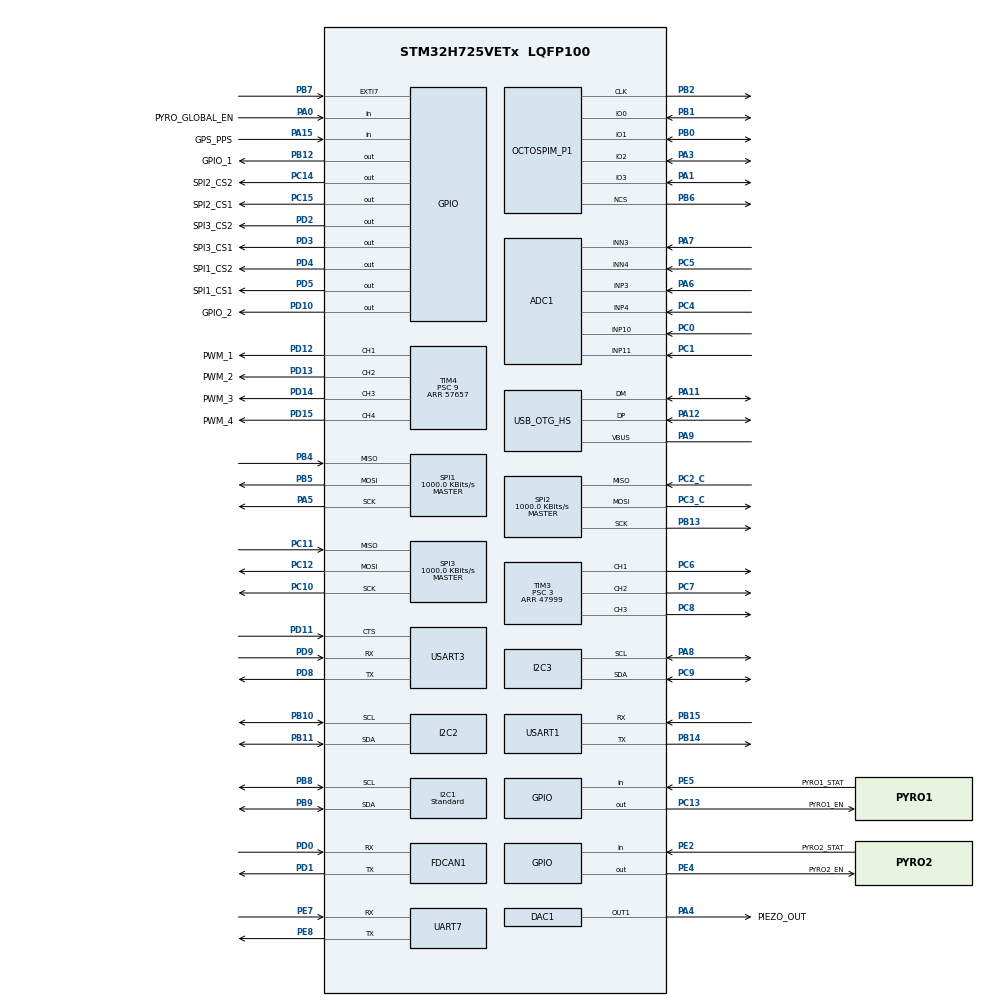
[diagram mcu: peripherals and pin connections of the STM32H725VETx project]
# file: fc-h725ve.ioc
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ADC1.Channel-0\#ChannelRegularConversion=ADC_CHANNEL_3
ADC1.NbrOfConversionFlag=1
ADC1.OffsetNumber-0\#ChannelRegularConversion=ADC_OFFSET_NONE
ADC1.OffsetSignedSaturation-0\#ChannelRegularConversion=DISABLE
ADC1.Rank-0\#ChannelRegularConversion=1
ADC1.SamplingTime-0\#ChannelRegularConversion=ADC_SAMPLETIME_1CYCLE_5
ADC1.SingleDiff-0\#ChannelRegularConversion=ADC_DIFFERENTIAL_ENDED
ADC1.master=1
CORTEX_M7.CPU_ICache=Enabled
CORTEX_M7.default_mode_Activation=1
DAC1.DAC_Channel-DAC_OUT1=DAC_CHANNEL_1
DAC1.DAC_Trigger-DAC_OUT1=DAC_TRIGGER_T5_TRGO
Dma.DAC1_CH1.0.Direction=DMA_MEMORY_TO_PERIPH
Dma.DAC1_CH1.0.EventEnable=DISABLE
Dma.DAC1_CH1.0.FIFOMode=DMA_FIFOMODE_DISABLE
Dma.DAC1_CH1.0.Instance=DMA1_Stream0
Dma.DAC1_CH1.0.MemDataAlignment=DMA_MDATAALIGN_BYTE
Dma.DAC1_CH1.0.MemInc=DMA_MINC_ENABLE
Dma.DAC1_CH1.0.Mode=DMA_CIRCULAR
Dma.DAC1_CH1.0.PeriphDataAlignment=DMA_PDATAALIGN_BYTE
Dma.DAC1_CH1.0.PeriphInc=DMA_PINC_DISABLE
Dma.DAC1_CH1.0.Polarity=HAL_DMAMUX_REQ_GEN_RISING
Dma.DAC1_CH1.0.Priority=DMA_PRIORITY_LOW
Dma.DAC1_CH1.0.RequestNumber=1
Dma.DAC1_CH1.0.SignalID=NONE
Dma.DAC1_CH1.0.SyncEnable=DISABLE
Dma.DAC1_CH1.0.SyncPolarity=HAL_DMAMUX_SYNC_NO_EVENT
Dma.DAC1_CH1.0.SyncRequestNumber=1
Dma.DAC1_CH1.0.SyncSignalID=NONE
Dma.Request0=DAC1_CH1
FDCAN1.CalculateBaudRateNominal=1000000
FDCAN1.CalculateTimeBitNominal=1000
FDCAN1.CalculateTimeQuantumNominal=333.3333333333333
FDCAN1.ClockCalibrationCCU=DISABLE
FDCAN1.DataPrescaler=8
FDCAN1.FrameFormat=FDCAN_FRAME_FD_NO_BRS
FDCAN1.NominalPrescaler=32
I2C1.I2C_Speed_Mode=I2C_Standard
I2C1.Timing=0x10B0DCFB
I2C2.Timing=0x10B0DCFB
I2C3.Timing=0x10B0DCFB
Mcu.Family=STM32H7
Mcu.Name=STM32H725VETx
Mcu.Package=LQFP100
NVIC.DMA1_Stream0_IRQn=true\:5\:0\:true\:false\:true\:false\:true\:true
NVIC.EXTI9_5_IRQn=true\:5\:0\:true\:false\:true\:true\:true\:true
NVIC.OTG_HS_IRQn=true\:5\:0\:true\:false\:true\:false\:true\:true
NVIC.PriorityGroup=NVIC_PRIORITYGROUP_4
NVIC.TIM6_DAC_IRQn=true\:15\:0\:false\:false\:true\:false\:true\:true
NVIC.TimeBase=TIM6_DAC_IRQn
NVIC.TimeBaseIP=TIM6
PA0.GPIO_Label=PYRO_GLOBAL_EN
PA0.Signal=GPIO_Input
PA1.Mode=OCTOSPI1_IOL_Port1L
PA1.Signal=OCTOSPIM_P1_IO3
PA11.Mode=Device_Only_FS
PA11.Signal=USB_OTG_HS_DM
PA12.Mode=Device_Only_FS
PA12.Signal=USB_OTG_HS_DP
PA13(JTMS/SWDIO).Mode=Trace_Asynchronous_SW
PA13(JTMS/SWDIO).Signal=DEBUG_JTMS-SWDIO
PA14(JTCK/SWCLK).Mode=Trace_Asynchronous_SW
PA14(JTCK/SWCLK).Signal=DEBUG_JTCK-SWCLK
PA15(JTDI).GPIO_Label=GPS_PPS
PA15(JTDI).Signal=GPIO_Input
PA3.Mode=OCTOSPI1_IOL_Port1L
PA3.Signal=OCTOSPIM_P1_IO2
PA4.GPIO_Label=PIEZO_OUT
PA4.Signal=COMP_DAC11_group
PA5.Mode=Full_Duplex_Master
PA5.Signal=SPI1_SCK
PA6.Signal=ADCx_INP3
PA7.Signal=ADCx_INN3
PA8.GPIO_Pu=GPIO_NOPULL
PA8.Mode=I2C
PA8.Signal=I2C3_SCL
PA9.Mode=Activate_VBUS_FS
PA9.Signal=USB_OTG_HS_VBUS
PB0.Mode=OCTOSPI1_IOL_Port1L
PB0.Signal=OCTOSPIM_P1_IO1
PB1.Mode=OCTOSPI1_IOL_Port1L
PB1.Signal=OCTOSPIM_P1_IO0
PB10.GPIO_Pu=GPIO_NOPULL
PB10.Mode=I2C
PB10.Signal=I2C2_SCL
PB11.GPIO_Pu=GPIO_NOPULL
PB11.Mode=I2C
PB11.Signal=I2C2_SDA
PB12.GPIO_Label=GPIO_1
PB12.Signal=GPIO_Output
PB13.Mode=Full_Duplex_Master
PB13.Signal=SPI2_SCK
PB14.Mode=Asynchronous
PB14.Signal=USART1_TX
PB15.Mode=Asynchronous
PB15.Signal=USART1_RX
PB2.Mode=O1_P1_CLK
PB2.Signal=OCTOSPIM_P1_CLK
PB3(JTDO/TRACESWO).Mode=Trace_Asynchronous_SW
PB3(JTDO/TRACESWO).Signal=DEBUG_JTDO-SWO
PB4(NJTRST).Mode=Full_Duplex_Master
PB4(NJTRST).Signal=SPI1_MISO
PB5.Mode=Full_Duplex_Master
PB5.Signal=SPI1_MOSI
PB6.Mode=OCTOSPI1_Port1_NCS
PB6.Signal=OCTOSPIM_P1_NCS
PB7.Signal=GPXTI7
PB8.GPIO_Pu=GPIO_NOPULL
PB8.Mode=I2C
PB8.Signal=I2C1_SCL
PB9.GPIO_Pu=GPIO_NOPULL
PB9.Mode=I2C
PB9.Signal=I2C1_SDA
PC0.Signal=ADCx_INP10
PC1.Signal=ADCx_INP11
PC10.Mode=Full_Duplex_Master
PC10.Signal=SPI3_SCK
PC11.Mode=Full_Duplex_Master
PC11.Signal=SPI3_MISO
PC12.Mode=Full_Duplex_Master
PC12.Signal=SPI3_MOSI
PC13.GPIO_Label=PYRO1_EN
PC13.Signal=GPIO_Output
PC14-OSC32_IN.GPIO_Label=SPI2_CS2
PC14-OSC32_IN.Signal=GPIO_Output
PC15-OSC32_OUT.GPIO_Label=SPI2_CS1
PC15-OSC32_OUT.Signal=GPIO_Output
PC2_C.Mode=Full_Duplex_Master
PC2_C.Signal=SPI2_MISO
PC3_C.Mode=Full_Duplex_Master
PC3_C.Signal=SPI2_MOSI
PC4.Signal=ADCx_INP4
PC5.Signal=ADCx_INN4
PC6.Signal=S_TIM3_CH1
PC7.Signal=S_TIM3_CH2
PC8.Signal=S_TIM3_CH3
PC9.GPIO_Pu=GPIO_NOPULL
PC9.Mode=I2C
PC9.Signal=I2C3_SDA
PD0.Mode=FDCAN_Activate
PD0.Signal=FDCAN1_RX
PD1.Mode=FDCAN_Activate
PD1.Signal=FDCAN1_TX
PD10.GPIO_Label=GPIO_2
PD10.Signal=GPIO_Output
PD11.Mode=CTS_Only
PD11.Signal=USART3_CTS
PD12.GPIO_Label=PWM_1
PD12.Signal=S_TIM4_CH1
PD13.GPIO_Label=PWM_2
PD13.Signal=S_TIM4_CH2
PD14.GPIO_Label=PWM_3
PD14.Signal=S_TIM4_CH3
PD15.GPIO_Label=PWM_4
PD15.Signal=S_TIM4_CH4
PD2.GPIO_Label=SPI3_CS2
PD2.Signal=GPIO_Output
PD3.GPIO_Label=SPI3_CS1
PD3.Signal=GPIO_Output
PD4.GPIO_Label=SPI1_CS2
PD4.Signal=GPIO_Output
PD5.GPIO_Label=SPI1_CS1
PD5.Signal=GPIO_Output
PD8.Mode=Asynchronous
PD8.Signal=USART3_TX
PD9.Mode=Asynchronous
PD9.Signal=USART3_RX
PE2.GPIO_Label=PYRO2_STAT
PE2.Signal=GPIO_Input
PE4.GPIO_Label=PYRO2_EN
PE4.Signal=GPIO_Output
PE5.GPIO_Label=PYRO1_STAT
PE5.Signal=GPIO_Input
PE7.Mode=Asynchronous
PE7.Signal=UART7_RX
PE8.Mode=Asynchronous
PE8.Signal=UART7_TX
PH0-OSC_IN.Mode=HSE-External-Oscillator
PH0-OSC_IN.Signal=RCC_OSC_IN
PH1-OSC_OUT.Mode=HSE-External-Oscillator
PH1-OSC_OUT.Signal=RCC_OSC_OUT
ProjectManager.HeapSize=0x200
ProjectManager.StackSize=0x400
ProjectManager.TargetToolchain=CMake
RCC.ADCFreq_Value=96000000
RCC.APB1Freq_Value=96000000
RCC.APB2Freq_Value=96000000
RCC.APB3Freq_Value=96000000
RCC.APB4Freq_Value=96000000
RCC.CKPERSourceSelection=RCC_CLKPSOURCE_HSE
RCC.CortexFreq_Value=192000000
RCC.D1PPRE=RCC_APB3_DIV2
RCC.D2PPRE1=RCC_APB1_DIV2
RCC.D2PPRE2=RCC_APB2_DIV2
RCC.D3PPRE=RCC_APB4_DIV2
RCC.DIVM1=1
RCC.DIVM2=1
RCC.DIVN1=24
RCC.DIVN2=24
RCC.DIVP1=1
RCC.DIVQ1=4
RCC.EnbaleCSS=true
RCC.FDCANCLockSelection=RCC_FDCANCLKSOURCE_PLL2
RCC.HCLKFreq_Value=192000000
RCC.HSE_VALUE=8000000
RCC.PLL2FRACN=0
RCC.PLL3FRACN=0
RCC.PLLFRACN=0
RCC.PLLSourceVirtual=RCC_PLLSOURCE_HSE
RCC.QSPICLockSelection=RCC_OSPICLKSOURCE_PLL
RCC.SPI123CLockSelection=RCC_SPI123CLKSOURCE_CLKP
RCC.SYSCLKFreq_VALUE=192000000
RCC.SYSCLKSource=RCC_SYSCLKSOURCE_PLLCLK
RCC.SupplySource=PWR_LDO_SUPPLY
RCC.USBCLockSelection=RCC_USBCLKSOURCE_HSI48
RCC.USBFreq_Value=48000000
SH.ADCx_INN3.0=ADC1_INN3,IN3-Differential
SH.ADCx_INN4.0=ADC1_INN4,IN4-Differential
SH.ADCx_INP10.0=ADC1_INP10,IN10-Single-Ended
SH.ADCx_INP11.0=ADC1_INP11,IN11-Single-Ended
SH.ADCx_INP3.0=ADC1_INP3,IN3-Differential
SH.ADCx_INP4.0=ADC1_INP4,IN4-Differential
SH.COMP_DAC11_group.0=DAC1_OUT1,DAC_OUT1
SH.S_TIM3_CH1.0=TIM3_CH1,PWM Generation1 CH1
SH.S_TIM3_CH2.0=TIM3_CH2,PWM Generation2 CH2
SH.S_TIM3_CH3.0=TIM3_CH3,PWM Generation3 CH3
SH.S_TIM4_CH1.0=TIM4_CH1,PWM Generation1 CH1
SH.S_TIM4_CH2.0=TIM4_CH2,PWM Generation2 CH2
SH.S_TIM4_CH3.0=TIM4_CH3,PWM Generation3 CH3
SH.S_TIM4_CH4.0=TIM4_CH4,PWM Generation4 CH4
SPI1.BaudRatePrescaler=SPI_BAUDRATEPRESCALER_8
SPI1.CalculateBaudRate=1000.0 KBits/s
SPI1.DataSize=SPI_DATASIZE_8BIT
SPI1.Direction=SPI_DIRECTION_2LINES
SPI1.Mode=SPI_MODE_MASTER
SPI1.VirtualType=VM_MASTER
SPI2.BaudRatePrescaler=SPI_BAUDRATEPRESCALER_8
SPI2.CalculateBaudRate=1000.0 KBits/s
SPI2.DataSize=SPI_DATASIZE_8BIT
SPI2.Direction=SPI_DIRECTION_2LINES
SPI2.Mode=SPI_MODE_MASTER
SPI2.VirtualType=VM_MASTER
SPI3.BaudRatePrescaler=SPI_BAUDRATEPRESCALER_8
SPI3.CalculateBaudRate=1000.0 KBits/s
SPI3.DataSize=SPI_DATASIZE_8BIT
SPI3.Direction=SPI_DIRECTION_2LINES
SPI3.Mode=SPI_MODE_MASTER
SPI3.VirtualType=VM_MASTER
TIM3.Channel-PWM\ Generation1\ CH1=TIM_CHANNEL_1
TIM3.Channel-PWM\ Generation2\ CH2=TIM_CHANNEL_2
TIM3.Channel-PWM\ Generation3\ CH3=TIM_CHANNEL_3
TIM3.Period=47999
TIM3.Prescaler=3
TIM4.Channel-PWM\ Generation1\ CH1=TIM_CHANNEL_1
TIM4.Channel-PWM\ Generation2\ CH2=TIM_CHANNEL_2
TIM4.Channel-PWM\ Generation3\ CH3=TIM_CHANNEL_3
TIM4.Channel-PWM\ Generation4\ CH4=TIM_CHANNEL_4
TIM4.Period=57657
TIM4.Prescaler=9
TIM5.Period=499
TIM5.Prescaler=3
TIM5.TIM_MasterOutputTrigger=TIM_TRGO_UPDATE
USART1.VirtualMode-Asynchronous=VM_ASYNC
USART3.VirtualMode-Asynchronous=VM_ASYNC
USB_DEVICE.CLASS_NAME_HS=MSC
USB_DEVICE.VirtualMode=Msc
USB_DEVICE.VirtualModeHS=Msc_HS
USB_OTG_HS.VirtualMode-Device_Only_FS=Device_Only_FS
VP_MEMORYMAP_VS_MEMORYMAP.Mode=CurAppReg
VP_OCTOSPI1_VS_quad.Mode=quad_mode
VP_RCC_USB.Mode=USB_HS
VP_SYS_VS_tim6.Mode=TIM6
VP_TIM3_VS_ClockSourceINT.Mode=Internal
VP_TIM4_VS_ClockSourceINT.Mode=Internal
VP_TIM5_VS_ClockSourceINT.Mode=Internal
VP_USB_DEVICE_VS_USB_DEVICE_MSC_HS.Mode=MSC_HS
board=custom

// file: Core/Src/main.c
/* USER CODE BEGIN Header */
/**
  ******************************************************************************
  * @file           : main.c
  * @brief          : Main program body
  ******************************************************************************
  * @attention
  *
  * Copyright (c) 2026 STMicroelectronics.
  * All rights reserved.
  *
  * This software is licensed under terms that can be found in the LICENSE file
  * in the root directory of this software component.
  * If no LICENSE file comes with this software, it is provided AS-IS.
  *
  ******************************************************************************
  */
/* USER CODE END Header */
#include "main.h"
#include "usb_device.h"

/* USER CODE BEGIN Includes */
#include "shared_main.h"
/* USER CODE END Includes */

ADC_HandleTypeDef hadc1;

DAC_HandleTypeDef hdac1;
DMA_HandleTypeDef hdma_dac1_ch1;

FDCAN_HandleTypeDef hfdcan1;

I2C_HandleTypeDef hi2c1;
I2C_HandleTypeDef hi2c2;
I2C_HandleTypeDef hi2c3;

OSPI_HandleTypeDef hospi1;

SPI_HandleTypeDef hspi1;
SPI_HandleTypeDef hspi2;
SPI_HandleTypeDef hspi3;

TIM_HandleTypeDef htim3;
TIM_HandleTypeDef htim4;
TIM_HandleTypeDef htim5;

UART_HandleTypeDef huart7;
UART_HandleTypeDef huart1;
UART_HandleTypeDef huart3;

void SystemClock_Config(void);
void PeriphCommonClock_Config(void);
static void MPU_Config(void);
static void MX_GPIO_Init(void);
static void MX_DMA_Init(void);
static void MX_ADC1_Init(void);
static void MX_DAC1_Init(void);
static void MX_FDCAN1_Init(void);
static void MX_I2C1_Init(void);
static void MX_I2C2_Init(void);
static void MX_I2C3_Init(void);
static void MX_OCTOSPI1_Init(void);
static void MX_SPI1_Init(void);
static void MX_SPI2_Init(void);
static void MX_SPI3_Init(void);
static void MX_TIM3_Init(void);
static void MX_TIM4_Init(void);
static void MX_TIM5_Init(void);
static void MX_UART7_Init(void);
static void MX_USART1_UART_Init(void);
static void MX_USART3_UART_Init(void);

int main(void)
{

  /* MPU Configuration--------------------------------------------------------*/
  MPU_Config();

  /* Enable the CPU Cache */

  /* Enable I-Cache---------------------------------------------------------*/
  SCB_EnableICache();

  /* MCU Configuration--------------------------------------------------------*/

  /* Reset of all peripherals, Initializes the Flash interface and the Systick. */
  HAL_Init();

  /* Configure the system clock */
  SystemClock_Config();

  /* Configure the peripherals common clocks */
  PeriphCommonClock_Config();

  /* Initialize all configured peripherals */
  MX_GPIO_Init();
  MX_DMA_Init();
  MX_ADC1_Init();
  MX_DAC1_Init();
  MX_FDCAN1_Init();
  MX_I2C1_Init();
  MX_I2C2_Init();
  MX_I2C3_Init();
  MX_OCTOSPI1_Init();
  MX_SPI1_Init();
  MX_SPI2_Init();
  MX_SPI3_Init();
  MX_TIM3_Init();
  MX_TIM4_Init();
  MX_TIM5_Init();
  MX_UART7_Init();
  MX_USART1_UART_Init();
  MX_USART3_UART_Init();
  MX_USB_DEVICE_Init();
  /* USER CODE BEGIN 2 */

  shared_main();
  /* USER CODE END 2 */

  /* Infinite loop */
  while (1)
  {

  }
}

void SystemClock_Config(void)
{
  RCC_OscInitTypeDef RCC_OscInitStruct = {0};
  RCC_ClkInitTypeDef RCC_ClkInitStruct = {0};
  RCC_CRSInitTypeDef RCC_CRSInitStruct = {0};

  /** Supply configuration update enable
  */
  HAL_PWREx_ConfigSupply(PWR_LDO_SUPPLY);

  /** Configure the main internal regulator output voltage
  */
  __HAL_PWR_VOLTAGESCALING_CONFIG(PWR_REGULATOR_VOLTAGE_SCALE1);

  while(!__HAL_PWR_GET_FLAG(PWR_FLAG_VOSRDY)) {}

  /** Initializes the RCC Oscillators according to the specified parameters
  * in the RCC_OscInitTypeDef structure.
  */
  RCC_OscInitStruct.OscillatorType = RCC_OSCILLATORTYPE_HSI48|RCC_OSCILLATORTYPE_HSE;
  RCC_OscInitStruct.HSEState = RCC_HSE_ON;
  RCC_OscInitStruct.HSI48State = RCC_HSI48_ON;
  RCC_OscInitStruct.PLL.PLLState = RCC_PLL_ON;
  RCC_OscInitStruct.PLL.PLLSource = RCC_PLLSOURCE_HSE;
  RCC_OscInitStruct.PLL.PLLM = 1;
  RCC_OscInitStruct.PLL.PLLN = 24;
  RCC_OscInitStruct.PLL.PLLP = 1;
  RCC_OscInitStruct.PLL.PLLQ = 4;
  RCC_OscInitStruct.PLL.PLLR = 2;
  RCC_OscInitStruct.PLL.PLLRGE = RCC_PLL1VCIRANGE_3;
  RCC_OscInitStruct.PLL.PLLVCOSEL = RCC_PLL1VCOWIDE;
  RCC_OscInitStruct.PLL.PLLFRACN = 0;
  if (HAL_RCC_OscConfig(&RCC_OscInitStruct) != HAL_OK)
  {
    Error_Handler();
  }

  /** Initializes the CPU, AHB and APB buses clocks
  */
  RCC_ClkInitStruct.ClockType = RCC_CLOCKTYPE_HCLK|RCC_CLOCKTYPE_SYSCLK
                              |RCC_CLOCKTYPE_PCLK1|RCC_CLOCKTYPE_PCLK2
                              |RCC_CLOCKTYPE_D3PCLK1|RCC_CLOCKTYPE_D1PCLK1;
  RCC_ClkInitStruct.SYSCLKSource = RCC_SYSCLKSOURCE_PLLCLK;
  RCC_ClkInitStruct.SYSCLKDivider = RCC_SYSCLK_DIV1;
  RCC_ClkInitStruct.AHBCLKDivider = RCC_HCLK_DIV1;
  RCC_ClkInitStruct.APB3CLKDivider = RCC_APB3_DIV2;
  RCC_ClkInitStruct.APB1CLKDivider = RCC_APB1_DIV2;
  RCC_ClkInitStruct.APB2CLKDivider = RCC_APB2_DIV2;
  RCC_ClkInitStruct.APB4CLKDivider = RCC_APB4_DIV2;

  if (HAL_RCC_ClockConfig(&RCC_ClkInitStruct, FLASH_LATENCY_2) != HAL_OK)
  {
    Error_Handler();
  }

  /** Enables the Clock Security System
  */
  HAL_RCC_EnableCSS();

  /** Enable the SYSCFG APB clock
  */
  __HAL_RCC_CRS_CLK_ENABLE();

  /** Configures CRS
  */
  RCC_CRSInitStruct.Prescaler = RCC_CRS_SYNC_DIV1;
  RCC_CRSInitStruct.Source = RCC_CRS_SYNC_SOURCE_USB2;
  RCC_CRSInitStruct.Polarity = RCC_CRS_SYNC_POLARITY_RISING;
  RCC_CRSInitStruct.ReloadValue = __HAL_RCC_CRS_RELOADVALUE_CALCULATE(48000000,1000);
  RCC_CRSInitStruct.ErrorLimitValue = 34;
  RCC_CRSInitStruct.HSI48CalibrationValue = 32;

  HAL_RCCEx_CRSConfig(&RCC_CRSInitStruct);
}

void PeriphCommonClock_Config(void)
{
  RCC_PeriphCLKInitTypeDef PeriphClkInitStruct = {0};

  /** Initializes the peripherals clock
  */
  PeriphClkInitStruct.PeriphClockSelection = RCC_PERIPHCLK_ADC|RCC_PERIPHCLK_FDCAN
                              |RCC_PERIPHCLK_CKPER;
  PeriphClkInitStruct.PLL2.PLL2M = 1;
  PeriphClkInitStruct.PLL2.PLL2N = 24;
  PeriphClkInitStruct.PLL2.PLL2P = 2;
  PeriphClkInitStruct.PLL2.PLL2Q = 2;
  PeriphClkInitStruct.PLL2.PLL2R = 2;
  PeriphClkInitStruct.PLL2.PLL2RGE = RCC_PLL2VCIRANGE_3;
  PeriphClkInitStruct.PLL2.PLL2VCOSEL = RCC_PLL2VCOWIDE;
  PeriphClkInitStruct.PLL2.PLL2FRACN = 0;
  PeriphClkInitStruct.CkperClockSelection = RCC_CLKPSOURCE_HSE;
  PeriphClkInitStruct.FdcanClockSelection = RCC_FDCANCLKSOURCE_PLL2;
  PeriphClkInitStruct.AdcClockSelection = RCC_ADCCLKSOURCE_PLL2;
  if (HAL_RCCEx_PeriphCLKConfig(&PeriphClkInitStruct) != HAL_OK)
  {
    Error_Handler();
  }
}

static void MX_ADC1_Init(void)
{

  ADC_MultiModeTypeDef multimode = {0};
  ADC_ChannelConfTypeDef sConfig = {0};

  /** Common config
  */
  hadc1.Instance = ADC1;
  hadc1.Init.ClockPrescaler = ADC_CLOCK_ASYNC_DIV1;
  hadc1.Init.Resolution = ADC_RESOLUTION_16B;
  hadc1.Init.ScanConvMode = ADC_SCAN_DISABLE;
  hadc1.Init.EOCSelection = ADC_EOC_SINGLE_CONV;
  hadc1.Init.LowPowerAutoWait = DISABLE;
  hadc1.Init.ContinuousConvMode = DISABLE;
  hadc1.Init.NbrOfConversion = 1;
  hadc1.Init.DiscontinuousConvMode = DISABLE;
  hadc1.Init.ExternalTrigConv = ADC_SOFTWARE_START;
  hadc1.Init.ExternalTrigConvEdge = ADC_EXTERNALTRIGCONVEDGE_NONE;
  hadc1.Init.ConversionDataManagement = ADC_CONVERSIONDATA_DR;
  hadc1.Init.Overrun = ADC_OVR_DATA_PRESERVED;
  hadc1.Init.LeftBitShift = ADC_LEFTBITSHIFT_NONE;
  hadc1.Init.OversamplingMode = DISABLE;
  hadc1.Init.Oversampling.Ratio = 1;
  if (HAL_ADC_Init(&hadc1) != HAL_OK)
  {
    Error_Handler();
  }

  /** Configure the ADC multi-mode
  */
  multimode.Mode = ADC_MODE_INDEPENDENT;
  if (HAL_ADCEx_MultiModeConfigChannel(&hadc1, &multimode) != HAL_OK)
  {
    Error_Handler();
  }

  /** Configure Regular Channel
  */
  sConfig.Channel = ADC_CHANNEL_3;
  sConfig.Rank = ADC_REGULAR_RANK_1;
  sConfig.SamplingTime = ADC_SAMPLETIME_1CYCLE_5;
  sConfig.SingleDiff = ADC_DIFFERENTIAL_ENDED;
  sConfig.OffsetNumber = ADC_OFFSET_NONE;
  sConfig.Offset = 0;
  sConfig.OffsetSignedSaturation = DISABLE;
  if (HAL_ADC_ConfigChannel(&hadc1, &sConfig) != HAL_OK)
  {
    Error_Handler();
  }

}

static void MX_DAC1_Init(void)
{

  DAC_ChannelConfTypeDef sConfig = {0};

  /** DAC Initialization
  */
  hdac1.Instance = DAC1;
  if (HAL_DAC_Init(&hdac1) != HAL_OK)
  {
    Error_Handler();
  }

  /** DAC channel OUT1 config
  */
  sConfig.DAC_SampleAndHold = DAC_SAMPLEANDHOLD_DISABLE;
  sConfig.DAC_Trigger = DAC_TRIGGER_T5_TRGO;
  sConfig.DAC_OutputBuffer = DAC_OUTPUTBUFFER_ENABLE;
  sConfig.DAC_ConnectOnChipPeripheral = DAC_CHIPCONNECT_DISABLE;
  sConfig.DAC_UserTrimming = DAC_TRIMMING_FACTORY;
  if (HAL_DAC_ConfigChannel(&hdac1, &sConfig, DAC_CHANNEL_1) != HAL_OK)
  {
    Error_Handler();
  }

}

static void MX_FDCAN1_Init(void)
{

  hfdcan1.Instance = FDCAN1;
  hfdcan1.Init.FrameFormat = FDCAN_FRAME_FD_NO_BRS;
  hfdcan1.Init.Mode = FDCAN_MODE_NORMAL;
  hfdcan1.Init.AutoRetransmission = DISABLE;
  hfdcan1.Init.TransmitPause = DISABLE;
  hfdcan1.Init.ProtocolException = DISABLE;
  hfdcan1.Init.NominalPrescaler = 32;
  hfdcan1.Init.NominalSyncJumpWidth = 1;
  hfdcan1.Init.NominalTimeSeg1 = 1;
  hfdcan1.Init.NominalTimeSeg2 = 1;
  hfdcan1.Init.DataPrescaler = 8;
  hfdcan1.Init.DataSyncJumpWidth = 1;
  hfdcan1.Init.DataTimeSeg1 = 1;
  hfdcan1.Init.DataTimeSeg2 = 1;
  hfdcan1.Init.MessageRAMOffset = 0;
  hfdcan1.Init.StdFiltersNbr = 0;
  hfdcan1.Init.ExtFiltersNbr = 0;
  hfdcan1.Init.RxFifo0ElmtsNbr = 0;
  hfdcan1.Init.RxFifo0ElmtSize = FDCAN_DATA_BYTES_8;
  hfdcan1.Init.RxFifo1ElmtsNbr = 0;
  hfdcan1.Init.RxFifo1ElmtSize = FDCAN_DATA_BYTES_8;
  hfdcan1.Init.RxBuffersNbr = 0;
  hfdcan1.Init.RxBufferSize = FDCAN_DATA_BYTES_8;
  hfdcan1.Init.TxEventsNbr = 0;
  hfdcan1.Init.TxBuffersNbr = 0;
  hfdcan1.Init.TxFifoQueueElmtsNbr = 0;
  hfdcan1.Init.TxFifoQueueMode = FDCAN_TX_FIFO_OPERATION;
  hfdcan1.Init.TxElmtSize = FDCAN_DATA_BYTES_8;
  if (HAL_FDCAN_Init(&hfdcan1) != HAL_OK)
  {
    Error_Handler();
  }

}

static void MX_I2C1_Init(void)
{

  hi2c1.Instance = I2C1;
  hi2c1.Init.Timing = 0x10B0DCFB;
  hi2c1.Init.OwnAddress1 = 0;
  hi2c1.Init.AddressingMode = I2C_ADDRESSINGMODE_7BIT;
  hi2c1.Init.DualAddressMode = I2C_DUALADDRESS_DISABLE;
  hi2c1.Init.OwnAddress2 = 0;
  hi2c1.Init.OwnAddress2Masks = I2C_OA2_NOMASK;
  hi2c1.Init.GeneralCallMode = I2C_GENERALCALL_DISABLE;
  hi2c1.Init.NoStretchMode = I2C_NOSTRETCH_DISABLE;
  if (HAL_I2C_Init(&hi2c1) != HAL_OK)
  {
    Error_Handler();
  }

  /** Configure Analogue filter
  */
  if (HAL_I2CEx_ConfigAnalogFilter(&hi2c1, I2C_ANALOGFILTER_ENABLE) != HAL_OK)
  {
    Error_Handler();
  }

  /** Configure Digital filter
  */
  if (HAL_I2CEx_ConfigDigitalFilter(&hi2c1, 0) != HAL_OK)
  {
    Error_Handler();
  }

}

static void MX_I2C2_Init(void)
{

  hi2c2.Instance = I2C2;
  hi2c2.Init.Timing = 0x10B0DCFB;
  hi2c2.Init.OwnAddress1 = 0;
  hi2c2.Init.AddressingMode = I2C_ADDRESSINGMODE_7BIT;
  hi2c2.Init.DualAddressMode = I2C_DUALADDRESS_DISABLE;
  hi2c2.Init.OwnAddress2 = 0;
  hi2c2.Init.OwnAddress2Masks = I2C_OA2_NOMASK;
  hi2c2.Init.GeneralCallMode = I2C_GENERALCALL_DISABLE;
  hi2c2.Init.NoStretchMode = I2C_NOSTRETCH_DISABLE;
  if (HAL_I2C_Init(&hi2c2) != HAL_OK)
  {
    Error_Handler();
  }

  /** Configure Analogue filter
  */
  if (HAL_I2CEx_ConfigAnalogFilter(&hi2c2, I2C_ANALOGFILTER_ENABLE) != HAL_OK)
  {
    Error_Handler();
  }

  /** Configure Digital filter
  */
  if (HAL_I2CEx_ConfigDigitalFilter(&hi2c2, 0) != HAL_OK)
  {
    Error_Handler();
  }

}

static void MX_I2C3_Init(void)
{

  hi2c3.Instance = I2C3;
  hi2c3.Init.Timing = 0x10B0DCFB;
  hi2c3.Init.OwnAddress1 = 0;
  hi2c3.Init.AddressingMode = I2C_ADDRESSINGMODE_7BIT;
  hi2c3.Init.DualAddressMode = I2C_DUALADDRESS_DISABLE;
  hi2c3.Init.OwnAddress2 = 0;
  hi2c3.Init.OwnAddress2Masks = I2C_OA2_NOMASK;
  hi2c3.Init.GeneralCallMode = I2C_GENERALCALL_DISABLE;
  hi2c3.Init.NoStretchMode = I2C_NOSTRETCH_DISABLE;
  if (HAL_I2C_Init(&hi2c3) != HAL_OK)
  {
    Error_Handler();
  }

  /** Configure Analogue filter
  */
  if (HAL_I2CEx_ConfigAnalogFilter(&hi2c3, I2C_ANALOGFILTER_ENABLE) != HAL_OK)
  {
    Error_Handler();
  }

  /** Configure Digital filter
  */
  if (HAL_I2CEx_ConfigDigitalFilter(&hi2c3, 0) != HAL_OK)
  {
    Error_Handler();
  }

}

static void MX_OCTOSPI1_Init(void)
{

  OSPIM_CfgTypeDef sOspiManagerCfg = {0};

  /* OCTOSPI1 parameter configuration*/
  hospi1.Instance = OCTOSPI1;
  hospi1.Init.FifoThreshold = 1;
  hospi1.Init.DualQuad = HAL_OSPI_DUALQUAD_DISABLE;
  hospi1.Init.MemoryType = HAL_OSPI_MEMTYPE_MICRON;
  hospi1.Init.DeviceSize = 32;
  hospi1.Init.ChipSelectHighTime = 1;
  hospi1.Init.FreeRunningClock = HAL_OSPI_FREERUNCLK_DISABLE;
  hospi1.Init.ClockMode = HAL_OSPI_CLOCK_MODE_0;
  hospi1.Init.WrapSize = HAL_OSPI_WRAP_NOT_SUPPORTED;
  hospi1.Init.ClockPrescaler = 1;
  hospi1.Init.SampleShifting = HAL_OSPI_SAMPLE_SHIFTING_NONE;
  hospi1.Init.DelayHoldQuarterCycle = HAL_OSPI_DHQC_DISABLE;
  hospi1.Init.ChipSelectBoundary = 0;
  hospi1.Init.DelayBlockBypass = HAL_OSPI_DELAY_BLOCK_BYPASSED;
  hospi1.Init.MaxTran = 0;
  hospi1.Init.Refresh = 0;
  if (HAL_OSPI_Init(&hospi1) != HAL_OK)
  {
    Error_Handler();
  }
  sOspiManagerCfg.ClkPort = 1;
  sOspiManagerCfg.NCSPort = 1;
  sOspiManagerCfg.IOLowPort = HAL_OSPIM_IOPORT_1_LOW;
  if (HAL_OSPIM_Config(&hospi1, &sOspiManagerCfg, HAL_OSPI_TIMEOUT_DEFAULT_VALUE) != HAL_OK)
  {
    Error_Handler();
  }

}

static void MX_SPI1_Init(void)
{

  /* SPI1 parameter configuration*/
  hspi1.Instance = SPI1;
  hspi1.Init.Mode = SPI_MODE_MASTER;
  hspi1.Init.Direction = SPI_DIRECTION_2LINES;
  hspi1.Init.DataSize = SPI_DATASIZE_8BIT;
  hspi1.Init.CLKPolarity = SPI_POLARITY_LOW;
  hspi1.Init.CLKPhase = SPI_PHASE_1EDGE;
  hspi1.Init.NSS = SPI_NSS_SOFT;
  hspi1.Init.BaudRatePrescaler = SPI_BAUDRATEPRESCALER_8;
  hspi1.Init.FirstBit = SPI_FIRSTBIT_MSB;
  hspi1.Init.TIMode = SPI_TIMODE_DISABLE;
  hspi1.Init.CRCCalculation = SPI_CRCCALCULATION_DISABLE;
  hspi1.Init.CRCPolynomial = 0x0;
  hspi1.Init.NSSPMode = SPI_NSS_PULSE_ENABLE;
  hspi1.Init.NSSPolarity = SPI_NSS_POLARITY_LOW;
  hspi1.Init.FifoThreshold = SPI_FIFO_THRESHOLD_01DATA;
  hspi1.Init.TxCRCInitializationPattern = SPI_CRC_INITIALIZATION_ALL_ZERO_PATTERN;
  hspi1.Init.RxCRCInitializationPattern = SPI_CRC_INITIALIZATION_ALL_ZERO_PATTERN;
  hspi1.Init.MasterSSIdleness = SPI_MASTER_SS_IDLENESS_00CYCLE;
  hspi1.Init.MasterInterDataIdleness = SPI_MASTER_INTERDATA_IDLENESS_00CYCLE;
  hspi1.Init.MasterReceiverAutoSusp = SPI_MASTER_RX_AUTOSUSP_DISABLE;
  hspi1.Init.MasterKeepIOState = SPI_MASTER_KEEP_IO_STATE_DISABLE;
  hspi1.Init.IOSwap = SPI_IO_SWAP_DISABLE;
  if (HAL_SPI_Init(&hspi1) != HAL_OK)
  {
    Error_Handler();
  }

}

static void MX_SPI2_Init(void)
{

  /* SPI2 parameter configuration*/
  hspi2.Instance = SPI2;
  hspi2.Init.Mode = SPI_MODE_MASTER;
  hspi2.Init.Direction = SPI_DIRECTION_2LINES;
  hspi2.Init.DataSize = SPI_DATASIZE_8BIT;
  hspi2.Init.CLKPolarity = SPI_POLARITY_LOW;
  hspi2.Init.CLKPhase = SPI_PHASE_1EDGE;
  hspi2.Init.NSS = SPI_NSS_SOFT;
  hspi2.Init.BaudRatePrescaler = SPI_BAUDRATEPRESCALER_8;
  hspi2.Init.FirstBit = SPI_FIRSTBIT_MSB;
  hspi2.Init.TIMode = SPI_TIMODE_DISABLE;
  hspi2.Init.CRCCalculation = SPI_CRCCALCULATION_DISABLE;
  hspi2.Init.CRCPolynomial = 0x0;
  hspi2.Init.NSSPMode = SPI_NSS_PULSE_ENABLE;
  hspi2.Init.NSSPolarity = SPI_NSS_POLARITY_LOW;
  hspi2.Init.FifoThreshold = SPI_FIFO_THRESHOLD_01DATA;
  hspi2.Init.TxCRCInitializationPattern = SPI_CRC_INITIALIZATION_ALL_ZERO_PATTERN;
  hspi2.Init.RxCRCInitializationPattern = SPI_CRC_INITIALIZATION_ALL_ZERO_PATTERN;
  hspi2.Init.MasterSSIdleness = SPI_MASTER_SS_IDLENESS_00CYCLE;
  hspi2.Init.MasterInterDataIdleness = SPI_MASTER_INTERDATA_IDLENESS_00CYCLE;
  hspi2.Init.MasterReceiverAutoSusp = SPI_MASTER_RX_AUTOSUSP_DISABLE;
  hspi2.Init.MasterKeepIOState = SPI_MASTER_KEEP_IO_STATE_DISABLE;
  hspi2.Init.IOSwap = SPI_IO_SWAP_DISABLE;
  if (HAL_SPI_Init(&hspi2) != HAL_OK)
  {
    Error_Handler();
  }

}

static void MX_SPI3_Init(void)
{

  /* SPI3 parameter configuration*/
  hspi3.Instance = SPI3;
  hspi3.Init.Mode = SPI_MODE_MASTER;
  hspi3.Init.Direction = SPI_DIRECTION_2LINES;
  hspi3.Init.DataSize = SPI_DATASIZE_8BIT;
  hspi3.Init.CLKPolarity = SPI_POLARITY_LOW;
  hspi3.Init.CLKPhase = SPI_PHASE_1EDGE;
  hspi3.Init.NSS = SPI_NSS_SOFT;
  hspi3.Init.BaudRatePrescaler = SPI_BAUDRATEPRESCALER_8;
  hspi3.Init.FirstBit = SPI_FIRSTBIT_MSB;
  hspi3.Init.TIMode = SPI_TIMODE_DISABLE;
  hspi3.Init.CRCCalculation = SPI_CRCCALCULATION_DISABLE;
  hspi3.Init.CRCPolynomial = 0x0;
  hspi3.Init.NSSPMode = SPI_NSS_PULSE_ENABLE;
  hspi3.Init.NSSPolarity = SPI_NSS_POLARITY_LOW;
  hspi3.Init.FifoThreshold = SPI_FIFO_THRESHOLD_01DATA;
  hspi3.Init.TxCRCInitializationPattern = SPI_CRC_INITIALIZATION_ALL_ZERO_PATTERN;
  hspi3.Init.RxCRCInitializationPattern = SPI_CRC_INITIALIZATION_ALL_ZERO_PATTERN;
  hspi3.Init.MasterSSIdleness = SPI_MASTER_SS_IDLENESS_00CYCLE;
  hspi3.Init.MasterInterDataIdleness = SPI_MASTER_INTERDATA_IDLENESS_00CYCLE;
  hspi3.Init.MasterReceiverAutoSusp = SPI_MASTER_RX_AUTOSUSP_DISABLE;
  hspi3.Init.MasterKeepIOState = SPI_MASTER_KEEP_IO_STATE_DISABLE;
  hspi3.Init.IOSwap = SPI_IO_SWAP_DISABLE;
  if (HAL_SPI_Init(&hspi3) != HAL_OK)
  {
    Error_Handler();
  }

}

static void MX_TIM3_Init(void)
{

  TIM_ClockConfigTypeDef sClockSourceConfig = {0};
  TIM_MasterConfigTypeDef sMasterConfig = {0};
  TIM_OC_InitTypeDef sConfigOC = {0};

  htim3.Instance = TIM3;
  htim3.Init.Prescaler = 3;
  htim3.Init.CounterMode = TIM_COUNTERMODE_UP;
  htim3.Init.Period = 47999;
  htim3.Init.ClockDivision = TIM_CLOCKDIVISION_DIV1;
  htim3.Init.AutoReloadPreload = TIM_AUTORELOAD_PRELOAD_DISABLE;
  if (HAL_TIM_Base_Init(&htim3) != HAL_OK)
  {
    Error_Handler();
  }
  sClockSourceConfig.ClockSource = TIM_CLOCKSOURCE_INTERNAL;
  if (HAL_TIM_ConfigClockSource(&htim3, &sClockSourceConfig) != HAL_OK)
  {
    Error_Handler();
  }
  if (HAL_TIM_PWM_Init(&htim3) != HAL_OK)
  {
    Error_Handler();
  }
  sMasterConfig.MasterOutputTrigger = TIM_TRGO_RESET;
  sMasterConfig.MasterSlaveMode = TIM_MASTERSLAVEMODE_DISABLE;
  if (HAL_TIMEx_MasterConfigSynchronization(&htim3, &sMasterConfig) != HAL_OK)
  {
    Error_Handler();
  }
  sConfigOC.OCMode = TIM_OCMODE_PWM1;
  sConfigOC.Pulse = 0;
  sConfigOC.OCPolarity = TIM_OCPOLARITY_HIGH;
  sConfigOC.OCFastMode = TIM_OCFAST_DISABLE;
  if (HAL_TIM_PWM_ConfigChannel(&htim3, &sConfigOC, TIM_CHANNEL_1) != HAL_OK)
  {
    Error_Handler();
  }
  if (HAL_TIM_PWM_ConfigChannel(&htim3, &sConfigOC, TIM_CHANNEL_2) != HAL_OK)
  {
    Error_Handler();
  }
  if (HAL_TIM_PWM_ConfigChannel(&htim3, &sConfigOC, TIM_CHANNEL_3) != HAL_OK)
  {
    Error_Handler();
  }
  HAL_TIM_MspPostInit(&htim3);

}

static void MX_TIM4_Init(void)
{

  TIM_ClockConfigTypeDef sClockSourceConfig = {0};
  TIM_MasterConfigTypeDef sMasterConfig = {0};
  TIM_OC_InitTypeDef sConfigOC = {0};

  htim4.Instance = TIM4;
  htim4.Init.Prescaler = 9;
  htim4.Init.CounterMode = TIM_COUNTERMODE_UP;
  htim4.Init.Period = 57657;
  htim4.Init.ClockDivision = TIM_CLOCKDIVISION_DIV1;
  htim4.Init.AutoReloadPreload = TIM_AUTORELOAD_PRELOAD_DISABLE;
  if (HAL_TIM_Base_Init(&htim4) != HAL_OK)
  {
    Error_Handler();
  }
  sClockSourceConfig.ClockSource = TIM_CLOCKSOURCE_INTERNAL;
  if (HAL_TIM_ConfigClockSource(&htim4, &sClockSourceConfig) != HAL_OK)
  {
    Error_Handler();
  }
  if (HAL_TIM_PWM_Init(&htim4) != HAL_OK)
  {
    Error_Handler();
  }
  sMasterConfig.MasterOutputTrigger = TIM_TRGO_RESET;
  sMasterConfig.MasterSlaveMode = TIM_MASTERSLAVEMODE_DISABLE;
  if (HAL_TIMEx_MasterConfigSynchronization(&htim4, &sMasterConfig) != HAL_OK)
  {
    Error_Handler();
  }
  sConfigOC.OCMode = TIM_OCMODE_PWM1;
  sConfigOC.Pulse = 0;
  sConfigOC.OCPolarity = TIM_OCPOLARITY_HIGH;
  sConfigOC.OCFastMode = TIM_OCFAST_DISABLE;
  if (HAL_TIM_PWM_ConfigChannel(&htim4, &sConfigOC, TIM_CHANNEL_1) != HAL_OK)
  {
    Error_Handler();
  }
  if (HAL_TIM_PWM_ConfigChannel(&htim4, &sConfigOC, TIM_CHANNEL_2) != HAL_OK)
  {
    Error_Handler();
  }
  if (HAL_TIM_PWM_ConfigChannel(&htim4, &sConfigOC, TIM_CHANNEL_3) != HAL_OK)
  {
    Error_Handler();
  }
  if (HAL_TIM_PWM_ConfigChannel(&htim4, &sConfigOC, TIM_CHANNEL_4) != HAL_OK)
  {
    Error_Handler();
  }
  HAL_TIM_MspPostInit(&htim4);

}

static void MX_TIM5_Init(void)
{

  TIM_ClockConfigTypeDef sClockSourceConfig = {0};
  TIM_MasterConfigTypeDef sMasterConfig = {0};

  htim5.Instance = TIM5;
  htim5.Init.Prescaler = 3;
  htim5.Init.CounterMode = TIM_COUNTERMODE_UP;
  htim5.Init.Period = 499;
  htim5.Init.ClockDivision = TIM_CLOCKDIVISION_DIV1;
  htim5.Init.AutoReloadPreload = TIM_AUTORELOAD_PRELOAD_DISABLE;
  if (HAL_TIM_Base_Init(&htim5) != HAL_OK)
  {
    Error_Handler();
  }
  sClockSourceConfig.ClockSource = TIM_CLOCKSOURCE_INTERNAL;
  if (HAL_TIM_ConfigClockSource(&htim5, &sClockSourceConfig) != HAL_OK)
  {
    Error_Handler();
  }
  sMasterConfig.MasterOutputTrigger = TIM_TRGO_UPDATE;
  sMasterConfig.MasterSlaveMode = TIM_MASTERSLAVEMODE_DISABLE;
  if (HAL_TIMEx_MasterConfigSynchronization(&htim5, &sMasterConfig) != HAL_OK)
  {
    Error_Handler();
  }

}

static void MX_UART7_Init(void)
{

  huart7.Instance = UART7;
  huart7.Init.BaudRate = 115200;
  huart7.Init.WordLength = UART_WORDLENGTH_8B;
  huart7.Init.StopBits = UART_STOPBITS_1;
  huart7.Init.Parity = UART_PARITY_NONE;
  huart7.Init.Mode = UART_MODE_TX_RX;
  huart7.Init.HwFlowCtl = UART_HWCONTROL_NONE;
  huart7.Init.OverSampling = UART_OVERSAMPLING_16;
  huart7.Init.OneBitSampling = UART_ONE_BIT_SAMPLE_DISABLE;
  huart7.Init.ClockPrescaler = UART_PRESCALER_DIV1;
  huart7.AdvancedInit.AdvFeatureInit = UART_ADVFEATURE_NO_INIT;
  if (HAL_UART_Init(&huart7) != HAL_OK)
  {
    Error_Handler();
  }
  if (HAL_UARTEx_SetTxFifoThreshold(&huart7, UART_TXFIFO_THRESHOLD_1_8) != HAL_OK)
  {
    Error_Handler();
  }
  if (HAL_UARTEx_SetRxFifoThreshold(&huart7, UART_RXFIFO_THRESHOLD_1_8) != HAL_OK)
  {
    Error_Handler();
  }
  if (HAL_UARTEx_DisableFifoMode(&huart7) != HAL_OK)
  {
    Error_Handler();
  }

}

static void MX_USART1_UART_Init(void)
{

  huart1.Instance = USART1;
  huart1.Init.BaudRate = 115200;
  huart1.Init.WordLength = UART_WORDLENGTH_8B;
  huart1.Init.StopBits = UART_STOPBITS_1;
  huart1.Init.Parity = UART_PARITY_NONE;
  huart1.Init.Mode = UART_MODE_TX_RX;
  huart1.Init.HwFlowCtl = UART_HWCONTROL_NONE;
  huart1.Init.OverSampling = UART_OVERSAMPLING_16;
  huart1.Init.OneBitSampling = UART_ONE_BIT_SAMPLE_DISABLE;
  huart1.Init.ClockPrescaler = UART_PRESCALER_DIV1;
  huart1.AdvancedInit.AdvFeatureInit = UART_ADVFEATURE_NO_INIT;
  if (HAL_UART_Init(&huart1) != HAL_OK)
  {
    Error_Handler();
  }
  if (HAL_UARTEx_SetTxFifoThreshold(&huart1, UART_TXFIFO_THRESHOLD_1_8) != HAL_OK)
  {
    Error_Handler();
  }
  if (HAL_UARTEx_SetRxFifoThreshold(&huart1, UART_RXFIFO_THRESHOLD_1_8) != HAL_OK)
  {
    Error_Handler();
  }
  if (HAL_UARTEx_DisableFifoMode(&huart1) != HAL_OK)
  {
    Error_Handler();
  }

}

static void MX_USART3_UART_Init(void)
{

  huart3.Instance = USART3;
  huart3.Init.BaudRate = 115200;
  huart3.Init.WordLength = UART_WORDLENGTH_8B;
  huart3.Init.StopBits = UART_STOPBITS_1;
  huart3.Init.Parity = UART_PARITY_NONE;
  huart3.Init.Mode = UART_MODE_TX_RX;
  huart3.Init.HwFlowCtl = UART_HWCONTROL_CTS;
  huart3.Init.OverSampling = UART_OVERSAMPLING_16;
  huart3.Init.OneBitSampling = UART_ONE_BIT_SAMPLE_DISABLE;
  huart3.Init.ClockPrescaler = UART_PRESCALER_DIV1;
  huart3.AdvancedInit.AdvFeatureInit = UART_ADVFEATURE_NO_INIT;
  if (HAL_UART_Init(&huart3) != HAL_OK)
  {
    Error_Handler();
  }
  if (HAL_UARTEx_SetTxFifoThreshold(&huart3, UART_TXFIFO_THRESHOLD_1_8) != HAL_OK)
  {
    Error_Handler();
  }
  if (HAL_UARTEx_SetRxFifoThreshold(&huart3, UART_RXFIFO_THRESHOLD_1_8) != HAL_OK)
  {
    Error_Handler();
  }
  if (HAL_UARTEx_DisableFifoMode(&huart3) != HAL_OK)
  {
    Error_Handler();
  }

}

static void MX_DMA_Init(void)
{

  /* DMA controller clock enable */
  __HAL_RCC_DMA1_CLK_ENABLE();

  /* DMA interrupt init */
  /* DMA1_Stream0_IRQn interrupt configuration */
  HAL_NVIC_SetPriority(DMA1_Stream0_IRQn, 5, 0);
  HAL_NVIC_EnableIRQ(DMA1_Stream0_IRQn);

}

static void MX_GPIO_Init(void)
{
  GPIO_InitTypeDef GPIO_InitStruct = {0};

  /* GPIO Ports Clock Enable */
  __HAL_RCC_GPIOE_CLK_ENABLE();
  __HAL_RCC_GPIOC_CLK_ENABLE();
  __HAL_RCC_GPIOH_CLK_ENABLE();
  __HAL_RCC_GPIOA_CLK_ENABLE();
  __HAL_RCC_GPIOB_CLK_ENABLE();
  __HAL_RCC_GPIOD_CLK_ENABLE();

  /*Configure GPIO pin Output Level */
  HAL_GPIO_WritePin(PYRO2_EN_GPIO_Port, PYRO2_EN_Pin, GPIO_PIN_RESET);

  /*Configure GPIO pin Output Level */
  HAL_GPIO_WritePin(GPIOC, PYRO1_EN_Pin|SPI2_CS2_Pin|SPI2_CS1_Pin, GPIO_PIN_RESET);

  /*Configure GPIO pin Output Level */
  HAL_GPIO_WritePin(GPIO_1_GPIO_Port, GPIO_1_Pin, GPIO_PIN_RESET);

  /*Configure GPIO pin Output Level */
  HAL_GPIO_WritePin(GPIOD, GPIO_2_Pin|SPI3_CS2_Pin|SPI3_CS1_Pin|SPI1_CS2_Pin
                          |SPI1_CS1_Pin, GPIO_PIN_RESET);

  /*Configure GPIO pins : PYRO2_STAT_Pin PYRO1_STAT_Pin */
  GPIO_InitStruct.Pin = PYRO2_STAT_Pin|PYRO1_STAT_Pin;
  GPIO_InitStruct.Mode = GPIO_MODE_INPUT;
  GPIO_InitStruct.Pull = GPIO_NOPULL;
  HAL_GPIO_Init(GPIOE, &GPIO_InitStruct);

  /*Configure GPIO pin : PYRO2_EN_Pin */
  GPIO_InitStruct.Pin = PYRO2_EN_Pin;
  GPIO_InitStruct.Mode = GPIO_MODE_OUTPUT_PP;
  GPIO_InitStruct.Pull = GPIO_NOPULL;
  GPIO_InitStruct.Speed = GPIO_SPEED_FREQ_LOW;
  HAL_GPIO_Init(PYRO2_EN_GPIO_Port, &GPIO_InitStruct);

  /*Configure GPIO pins : PYRO1_EN_Pin SPI2_CS2_Pin SPI2_CS1_Pin */
  GPIO_InitStruct.Pin = PYRO1_EN_Pin|SPI2_CS2_Pin|SPI2_CS1_Pin;
  GPIO_InitStruct.Mode = GPIO_MODE_OUTPUT_PP;
  GPIO_InitStruct.Pull = GPIO_NOPULL;
  GPIO_InitStruct.Speed = GPIO_SPEED_FREQ_LOW;
  HAL_GPIO_Init(GPIOC, &GPIO_InitStruct);

  /*Configure GPIO pins : PYRO_GLOBAL_EN_Pin GPS_PPS_Pin */
  GPIO_InitStruct.Pin = PYRO_GLOBAL_EN_Pin|GPS_PPS_Pin;
  GPIO_InitStruct.Mode = GPIO_MODE_INPUT;
  GPIO_InitStruct.Pull = GPIO_NOPULL;
  HAL_GPIO_Init(GPIOA, &GPIO_InitStruct);

  /*Configure GPIO pin : GPIO_1_Pin */
  GPIO_InitStruct.Pin = GPIO_1_Pin;
  GPIO_InitStruct.Mode = GPIO_MODE_OUTPUT_PP;
  GPIO_InitStruct.Pull = GPIO_NOPULL;
  GPIO_InitStruct.Speed = GPIO_SPEED_FREQ_LOW;
  HAL_GPIO_Init(GPIO_1_GPIO_Port, &GPIO_InitStruct);

  /*Configure GPIO pins : GPIO_2_Pin SPI3_CS2_Pin SPI3_CS1_Pin SPI1_CS2_Pin
                           SPI1_CS1_Pin */
  GPIO_InitStruct.Pin = GPIO_2_Pin|SPI3_CS2_Pin|SPI3_CS1_Pin|SPI1_CS2_Pin
                          |SPI1_CS1_Pin;
  GPIO_InitStruct.Mode = GPIO_MODE_OUTPUT_PP;
  GPIO_InitStruct.Pull = GPIO_NOPULL;
  GPIO_InitStruct.Speed = GPIO_SPEED_FREQ_LOW;
  HAL_GPIO_Init(GPIOD, &GPIO_InitStruct);

  /*Configure GPIO pin : PB7 */
  GPIO_InitStruct.Pin = GPIO_PIN_7;
  GPIO_InitStruct.Mode = GPIO_MODE_IT_RISING;
  GPIO_InitStruct.Pull = GPIO_NOPULL;
  HAL_GPIO_Init(GPIOB, &GPIO_InitStruct);

  /* EXTI interrupt init*/
  HAL_NVIC_SetPriority(EXTI9_5_IRQn, 5, 0);
  HAL_NVIC_EnableIRQ(EXTI9_5_IRQn);

}

 /* MPU Configuration */

void MPU_Config(void)
{
  MPU_Region_InitTypeDef MPU_InitStruct = {0};

  /* Disables the MPU */
  HAL_MPU_Disable();

  /** Initializes and configures the Region and the memory to be protected
  */
  MPU_InitStruct.Enable = MPU_REGION_ENABLE;
  MPU_InitStruct.Number = MPU_REGION_NUMBER0;
  MPU_InitStruct.BaseAddress = 0x0;
  MPU_InitStruct.Size = MPU_REGION_SIZE_4GB;
  MPU_InitStruct.SubRegionDisable = 0x87;
  MPU_InitStruct.TypeExtField = MPU_TEX_LEVEL0;
  MPU_InitStruct.AccessPermission = MPU_REGION_NO_ACCESS;
  MPU_InitStruct.DisableExec = MPU_INSTRUCTION_ACCESS_DISABLE;
  MPU_InitStruct.IsShareable = MPU_ACCESS_SHAREABLE;
  MPU_InitStruct.IsCacheable = MPU_ACCESS_NOT_CACHEABLE;
  MPU_InitStruct.IsBufferable = MPU_ACCESS_NOT_BUFFERABLE;

  HAL_MPU_ConfigRegion(&MPU_InitStruct);
  /* Enables the MPU */
  HAL_MPU_Enable(MPU_PRIVILEGED_DEFAULT);

}

void HAL_TIM_PeriodElapsedCallback(TIM_HandleTypeDef *htim)
{
  if (htim->Instance == TIM6)
  {
    HAL_IncTick();
  }
}

void Error_Handler(void)
{
  __disable_irq();
  while (1)
  {
  }
}
